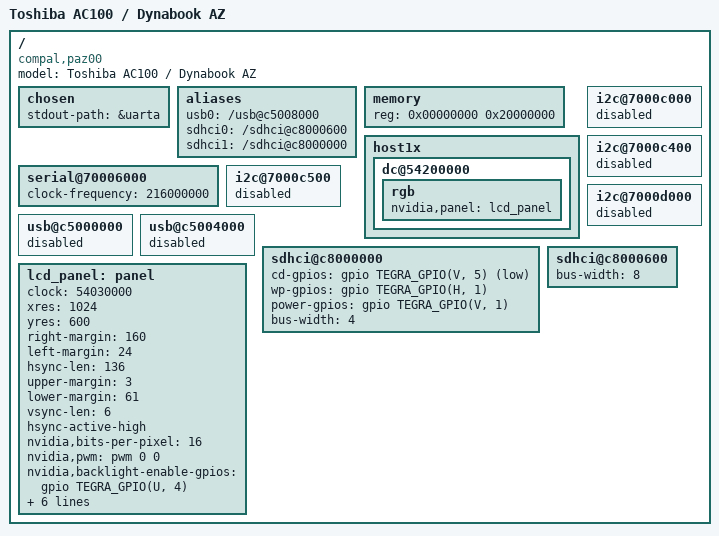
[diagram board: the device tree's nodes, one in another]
/dts-v1/;

#include "tegra20.dtsi"

/ {
	model = "Toshiba AC100 / Dynabook AZ";
	compatible = "compal,paz00", "nvidia,tegra20";

	chosen {
		stdout-path = &uarta;
	};

	aliases {
		usb0 = "/usb@c5008000";
		sdhci0 = "/sdhci@c8000600";
		sdhci1 = "/sdhci@c8000000";
	};

	memory {
		reg = <0x00000000 0x20000000>;
	};

	host1x {
		status = "okay";
		dc@54200000 {
			status = "okay";
			rgb {
				status = "okay";
				nvidia,panel = <&lcd_panel>;
			};
		};
	};

	serial@70006000 {
		clock-frequency = < 216000000 >;
	};

	i2c@7000c000 {
		status = "disabled";
	};

	i2c@7000c400 {
		status = "disabled";
	};

	i2c@7000c500 {
		status = "disabled";
	};

	i2c@7000d000 {
		status = "disabled";
	};

	usb@c5000000 {
		status = "disabled";
	};

	usb@c5004000 {
		status = "disabled";
	};

	sdhci@c8000000 {
		status = "okay";
		cd-gpios = <&gpio TEGRA_GPIO(V, 5) GPIO_ACTIVE_LOW>;
		wp-gpios = <&gpio TEGRA_GPIO(H, 1) GPIO_ACTIVE_HIGH>;
		power-gpios = <&gpio TEGRA_GPIO(V, 1) GPIO_ACTIVE_HIGH>;
		bus-width = <4>;
	};

	sdhci@c8000600 {
		status = "okay";
		bus-width = <8>;
	};

	lcd_panel: panel {
		/* PAZ00 has 1024x600 */
		clock = <54030000>;
		xres = <1024>;
		yres = <600>;
		right-margin = <160>;
		left-margin = <24>;
		hsync-len = <136>;
		upper-margin = <3>;
		lower-margin = <61>;
		vsync-len = <6>;
		hsync-active-high;
		nvidia,bits-per-pixel = <16>;
		nvidia,pwm = <&pwm 0 0>;
		nvidia,backlight-enable-gpios = <&gpio TEGRA_GPIO(U, 4)
							GPIO_ACTIVE_HIGH>;
		nvidia,lvds-shutdown-gpios = <&gpio TEGRA_GPIO(M, 6)
							GPIO_ACTIVE_HIGH>;
		nvidia,backlight-vdd-gpios = <&gpio TEGRA_GPIO(W, 0)
							GPIO_ACTIVE_HIGH>;
		nvidia,panel-vdd-gpios = <&gpio TEGRA_GPIO(A, 4)
							GPIO_ACTIVE_HIGH>;
		nvidia,panel-timings = <400 4 203 17 15>;
	};
};
